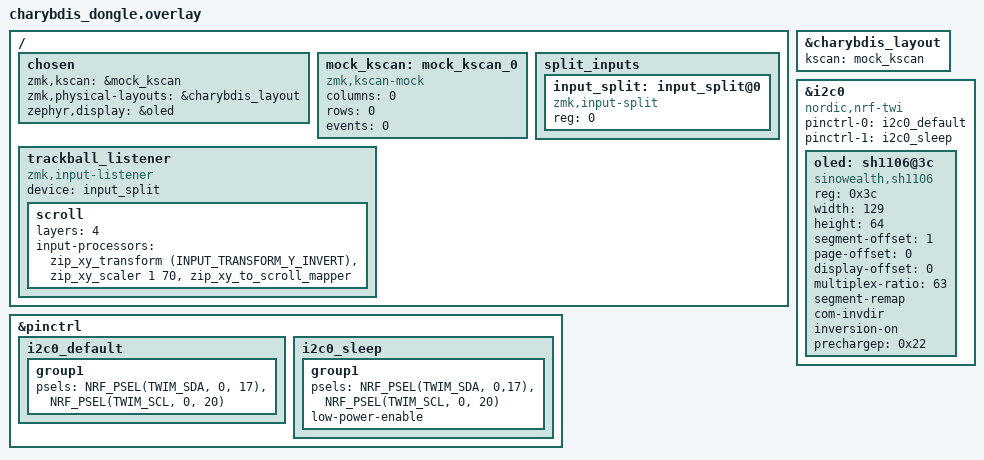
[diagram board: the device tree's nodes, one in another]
/*
 * Copyright (c) 2020 ZMK Contributors
 *
 * SPDX-License-Identifier: MIT
 */

#include "charybdis.dtsi"
#include <input/processors.dtsi>
#include <dt-bindings/input/input-event-codes.h>
#include <dt-bindings/zmk/input_transform.h>

/delete-node/ &kscan0;

&charybdis_layout {
    kscan = <&mock_kscan>;
};

/ {
    chosen {
        zmk,kscan = &mock_kscan;
        zmk,physical-layouts = &charybdis_layout;
        zephyr,display = &oled;
    };

    mock_kscan: mock_kscan_0 {
        compatible = "zmk,kscan-mock";
        columns = <0>;
        rows = <0>;
        events = <0>;
    };

    split_inputs {
        #address-cells = <1>;
        #size-cells = <0>;
        input_split: input_split@0 {
            compatible = "zmk,input-split";
            status = "okay";
            reg = <0>;
        };
    };

    trackball_listener {
        compatible = "zmk,input-listener";
        device = <&input_split>;

        scroll {
            layers = <4>;
            input-processors = <&zip_xy_transform (INPUT_TRANSFORM_Y_INVERT)>, <&zip_xy_scaler 1 70>, <&zip_xy_to_scroll_mapper>;
        };
    };
};

&pinctrl {
    i2c0_default: i2c0_default {
        group1 {
            psels = <NRF_PSEL(TWIM_SDA, 0, 17)>,
                <NRF_PSEL(TWIM_SCL, 0, 20)>;
        };
    };

    i2c0_sleep: i2c0_sleep {
        group1 {
            psels = <NRF_PSEL(TWIM_SDA, 0,17)>,
                <NRF_PSEL(TWIM_SCL, 0, 20)>;
                low-power-enable;
        };
    };
};

&i2c0 {
    status = "okay";
    compatible = "nordic,nrf-twi";
    pinctrl-0 = <&i2c0_default>;
    pinctrl-1 = <&i2c0_sleep>;
    oled: sh1106@3c {
        compatible = "sinowealth,sh1106";
        reg = <0x3c>;
        width = <129>;
        height = <64>;
        segment-offset = <1>;
        page-offset = <0>;
        display-offset = <0>;
        multiplex-ratio = <63>;
        segment-remap;
        com-invdir;
        inversion-on;
        prechargep = <0x22>;
    };
};
